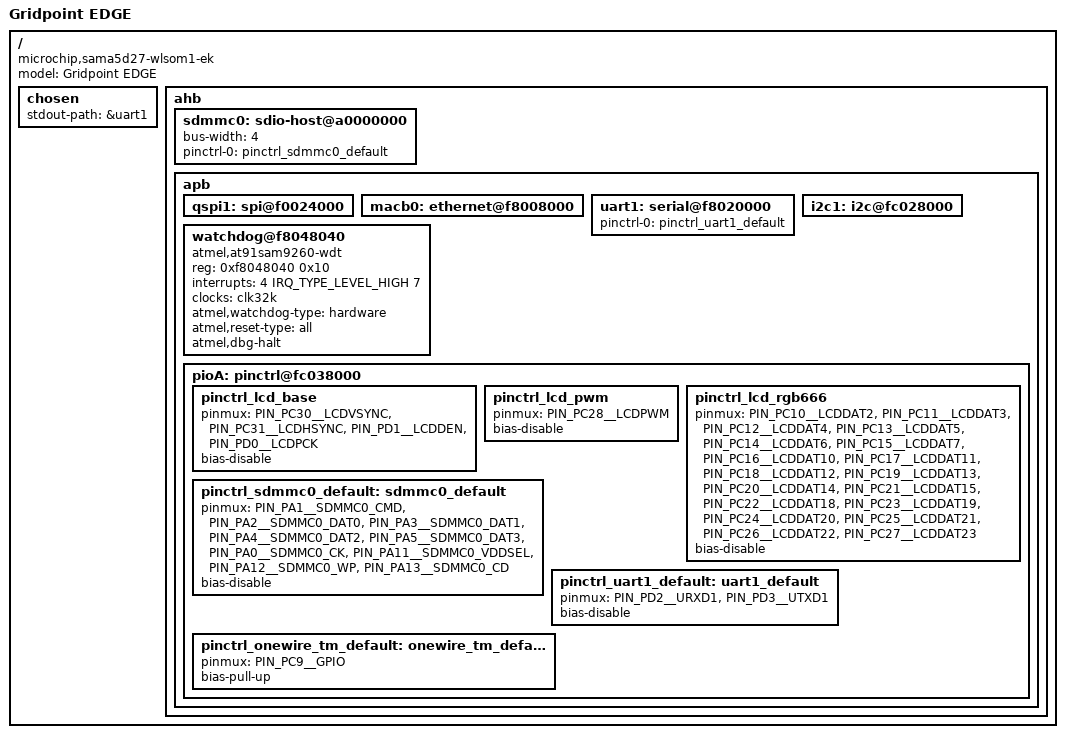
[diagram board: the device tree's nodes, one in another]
// SPDX-License-Identifier: (GPL-2.0+ OR MIT)
/*
 * at91-sama5d27_wlsom1_ek.dts - Device Tree file for SAMA5D27 WLSOM1 EK
 *
 * Copyright (C) 2019 Microchip Technology Inc. and its subsidiaries
 *
 * Author: Nicolas Ferre <nicolas.ferre@microcihp.com>
 */
/dts-v1/;
#include <dt-bindings/gpio/gpio.h>
#include "sama5d27_wlsom1.dtsi"

/ {
	model = "Gridpoint EDGE";
	compatible = "microchip,sama5d27-wlsom1-ek", "microchip,sama5d27-wlsom1", "atmel,sama5d2", "atmel,sama5";

	chosen {
		stdout-path = &uart1;
	};

	ahb {
		sdmmc0: sdio-host@a0000000 {
			bus-width = <4>;
			pinctrl-names = "default";
			pinctrl-0 = <&pinctrl_sdmmc0_default>;
			status = "okay";
		};

		apb {
			qspi1: spi@f0024000 {
				status = "okay";
			};

			macb0: ethernet@f8008000 {
				status = "okay";
			};

			uart1: serial@f8020000 {
				pinctrl-names = "default";
				pinctrl-0 = <&pinctrl_uart1_default>;
				status = "okay";
				bootph-all;
			};

			i2c1: i2c@fc028000 {
				status = "okay";
				bootph-all;
			};

			watchdog@f8048040 {
				compatible = "atmel,at91sam9260-wdt";
				reg = <0xf8048040 0x10>;
				interrupts = <4 IRQ_TYPE_LEVEL_HIGH 7>;
				clocks = <&clk32k>;
				atmel,watchdog-type = "hardware";
				atmel,reset-type = "all";
				atmel,dbg-halt;
				status = "okay";
			};

			pioA: pinctrl@fc038000 {
				pinctrl_lcd_base: pinctrl_lcd_base {
					pinmux = <PIN_PC30__LCDVSYNC>,
						 <PIN_PC31__LCDHSYNC>,
						 <PIN_PD1__LCDDEN>,
						 <PIN_PD0__LCDPCK>;
					bias-disable;
				};

				pinctrl_lcd_pwm: pinctrl_lcd_pwm {
					pinmux = <PIN_PC28__LCDPWM>;
					bias-disable;
				};

				pinctrl_lcd_rgb666: pinctrl_lcd_rgb666 {
					pinmux = <PIN_PC10__LCDDAT2>,
						 <PIN_PC11__LCDDAT3>,
						 <PIN_PC12__LCDDAT4>,
						 <PIN_PC13__LCDDAT5>,
						 <PIN_PC14__LCDDAT6>,
						 <PIN_PC15__LCDDAT7>,
						 <PIN_PC16__LCDDAT10>,
						 <PIN_PC17__LCDDAT11>,
						 <PIN_PC18__LCDDAT12>,
						 <PIN_PC19__LCDDAT13>,
						 <PIN_PC20__LCDDAT14>,
						 <PIN_PC21__LCDDAT15>,
						 <PIN_PC22__LCDDAT18>,
						 <PIN_PC23__LCDDAT19>,
						 <PIN_PC24__LCDDAT20>,
						 <PIN_PC25__LCDDAT21>,
						 <PIN_PC26__LCDDAT22>,
						 <PIN_PC27__LCDDAT23>;
					bias-disable;
				};

				pinctrl_sdmmc0_default: sdmmc0_default {
					pinmux = <PIN_PA1__SDMMC0_CMD>,
						 <PIN_PA2__SDMMC0_DAT0>,
						 <PIN_PA3__SDMMC0_DAT1>,
						 <PIN_PA4__SDMMC0_DAT2>,
						 <PIN_PA5__SDMMC0_DAT3>,
						 <PIN_PA0__SDMMC0_CK>,
						 <PIN_PA11__SDMMC0_VDDSEL>,
						 <PIN_PA12__SDMMC0_WP>,
						 <PIN_PA13__SDMMC0_CD>;
					bias-disable;
				};

				pinctrl_uart1_default: uart1_default {
					pinmux = <PIN_PD2__URXD1>,
						 <PIN_PD3__UTXD1>;
					bias-disable;
					bootph-all;
				};

				pinctrl_onewire_tm_default: onewire_tm_default {
					pinmux = <PIN_PC9__GPIO>;
					bias-pull-up;
				};
			};
		};
	};
};
